# CY8C5888LTI_LP097 register map
File version: 0.1
CY8C58LP
Registers are 8-bit, read-write, no defined reset value unless marked. A register's access mark holds for its fields unless they carry their own. Offsets are from the block's base; lines under a group give offsets from that group; [hi:lo] are bit positions; {n}, {i} and the like mark numbered series; 'fields as' and 'values as' point back to an identical list; <NAME> marks a mode.

## Memory map
0x00000000 UART
0x00000000 FanController

## UART
Base 0x00000000
0x40006449 TX_UART_TX_DATA — TX Data Register
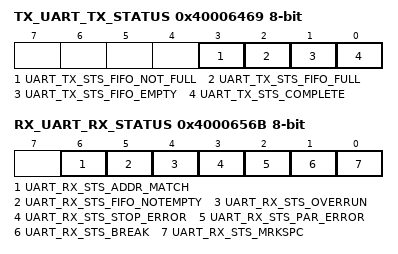
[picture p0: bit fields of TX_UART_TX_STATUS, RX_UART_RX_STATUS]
0x40006469 TX_UART_TX_STATUS — TX status register
  [3] UART_TX_STS_FIFO_NOT_FULL ro, [2] UART_TX_STS_FIFO_FULL ro, [1] UART_TX_STS_FIFO_EMPTY ro, [0] UART_TX_STS_COMPLETE ro
0x4000652B RX_UART_RX_ADDRESS1 — RX Address1 Register
0x4000653B RX_UART_RX_ADDRESS2 — RX Address2 Register
0x4000654B RX_UART_RX_DATA — RX Data Register
0x4000656B RX_UART_RX_STATUS — RX status register
  [6] UART_RX_STS_ADDR_MATCH ro, [5] UART_RX_STS_FIFO_NOTEMPTY ro, [4] UART_RX_STS_OVERRUN ro, [3] UART_RX_STS_STOP_ERROR ro, [2] UART_RX_STS_PAR_ERROR ro, [1] UART_RX_STS_BREAK ro, [0] UART_RX_STS_MRKSPC ro

## FanController
Base 0x00000000
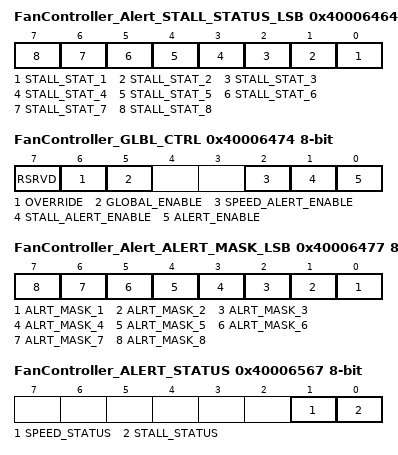
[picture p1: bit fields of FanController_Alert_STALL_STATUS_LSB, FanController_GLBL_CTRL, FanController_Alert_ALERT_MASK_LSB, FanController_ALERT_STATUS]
0x40006464 FanController_Alert_STALL_STATUS_LSB — Stall Status LSB Register
  [n-1] STALL_STAT_{n} (n=1..8) — Stall status for Fan{n}
0x40006474 FanController_GLBL_CTRL — Global Control Register
  [7] RSRVD ro — Reserved
  [6] OVERRIDE — HW mode override bit
    0=OVRD_DISABLED (HW control not overrided); 1=OVRD_ENABLED (HW control overrided)
  [5] GLOBAL_ENABLE — Global enable signal for the component
    0=COMP_DISABLED (Component disabled); 1=COMP_ENABLED (Component is enabled)
  [2] SPEED_ALERT_ENABLE — Speed alert enable signal
    0=SPEED_ALRT_DIS (Generation of speed alert is disabled); 1=SPEED_ALRT_EN (Generation of speed alert is enabled)
  [1] STALL_ALERT_ENABLE — Stall alert enable signal
    0=STALL_ALRT_DIS (Generation of stall alert is disabled); 1=STALL_ALRT_EN (Generation of stall alert is enabled)
  [0] ALERT_ENABLE — Global alert enable signal
    0=ALERTS_DIS (Generation of all alerts is disabled); 1=ALERTS_EN (Generation of alerts is enabled)
0x40006477 FanController_Alert_ALERT_MASK_LSB — Alert Mask LSB Register
  [n-1] ALRT_MASK_{n} (n=1..8) — Alert Mask for Fan{n}
0x40006567 FanController_ALERT_STATUS — Alert Status Register
  [1] SPEED_STATUS ro — Speed status for all Fans
    0=NO_SPEED_ERROR (No speed error occurred); 1=SPEED_ERROR (Speed error is occurred)
  [0] STALL_STATUS ro — Stall status for all Fans
    0=NO_STALL (No stall occurred); 1=STALL (Stall is occurred)
